# i2c_reva_me13 register map
Registers are 32-bit, access not given, no defined reset value unless marked. A register's access mark holds for its fields unless they carry their own. Offsets are from the block's base; lines under a group give offsets from that group; [hi:lo] are bit positions; {n}, {i} and the like mark numbered series; 'fields as' and 'values as' point back to an identical list; <NAME> marks a mode.

## Memory map
0x4001D000 I2C0 size 0x1000 — Inter-Integrated Circuit.

## Interrupts
13 I2C0 — I2C0 IRQ

## I2C0 — Inter-Integrated Circuit.
Base 0x4001D000
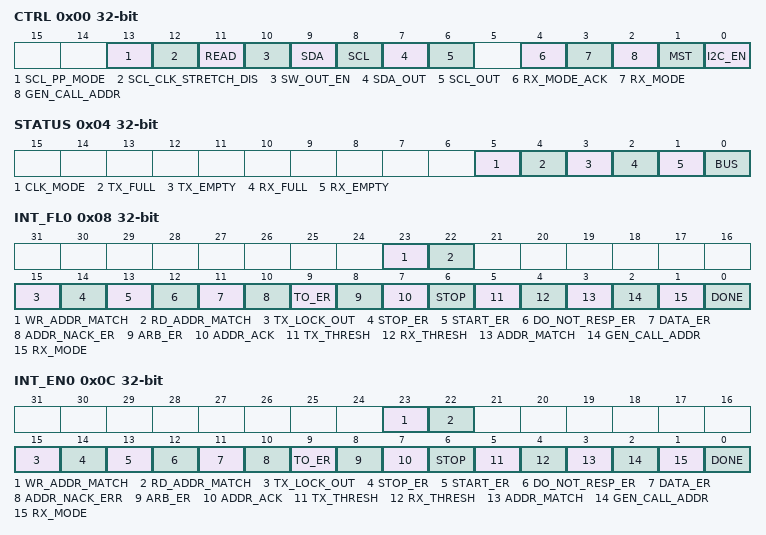
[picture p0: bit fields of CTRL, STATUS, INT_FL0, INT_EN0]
0x00 CTRL access per field — Control Register0.
  [13] SCL_PP_MODE rw — SCL Push-Pull Mode. This bit controls whether SCL is operated in a the I2C standard open-drain mode, or in a non-standard push-pull mode where the Hi-Z output isreplaced with Drive-1. The non-standard mode should only be used when operating as a master and communicating with slaves that are guaranteed to never drive SCL low.
    0=dis (Standard open-drain operation: drive low for 0, Hi-Z for 1); 1=en (Non-standard push-pull operation: drive low for 0, drive high for 1)
  [12] SCL_CLK_STRETCH_DIS rw — This bit will disable slave clock stretching when set.
    0=en (Slave clock stretching enabled.); 1=dis (Slave clock stretching disabled.)
  [11] READ ro — Read. This bit reflects the R/W bit of an address match (AMI = 1) or general call match (GCI = 1). This bit is valid 3 cycles after the relevant interrupt bit is set.
    0=write; 1=read
  [10] SW_OUT_EN rw — Software Output Enable.
    0=outputs_disable (I2C Outputs SCLO and SDAO disabled.); 1=outputs_enable (I2C Outputs SCLO and SDAO enabled.)
  [9] SDA ro — SDA status. THis bit reflects the logic gate of SDA signal.
  [8] SCL ro — SCL status. This bit reflects the logic gate of SCL signal.
  [7] SDA_OUT rw — SDA Output. This bits control SDA output when SWOE = 1.
    0=drive_sda_low; 1=release_sda
  [6] SCL_OUT rw — SCL Output. This bits control SCL output when SWOE =1.
    0=drive_scl_low; 1=release_scl
  [4] RX_MODE_ACK rw — Data Acknowledge. This bit defines the acknowledge bit returned by the I2C receiver while IRXM = 1 HW forces ACK to 0 when IRXM = 0.
    0=ack (return ACK (pulling SDA LOW).); 1=nack (return NACK (leaving SDA HIGH).)
  [3] RX_MODE rw — Interactive Receive Mode.
    0=dis (Disable Interactive Receive Mode.); 1=en (Enable Interactive Receive Mode.)
  [2] GEN_CALL_ADDR rw — General Call Address Enable.
    0=dis (Ignore Gneral Call Address.); 1=en (Acknowledge general call address.)
  [1] MST rw — Master Mode Enable.
    0=slave_mode; 1=master_mode
  [0] I2C_EN rw — I2C Enable.
    0=dis (Disable I2C.); 1=en (Enable I2C.)
0x04 STATUS
  [5] CLK_MODE ro — Clock Mode.
    0=not_actively_driving_scl_clock (Device not actively driving SCL clock cycles.); 1=actively_driving_scl_clock (Device operating as master and actively driving SCL clock cycles.)
  [4] TX_FULL
    0=not_empty; 1=empty
  [3] TX_EMPTY
    0=not_empty; 1=empty
  [2] RX_FULL ro
    0=not_full; 1=full
  [1] RX_EMPTY ro
    0=not_empty; 1=empty
  [0] BUS ro — Bus Status.
    0=idle (I2C Bus Idle.); 1=busy (I2C Bus Busy.)
0x08 INT_FL0 — Interrupt Status Register.
  [23] WR_ADDR_MATCH — Slave Write Address Match Interrupt
    0=no_match (No address match.); 1=match (Address match.)
  [22] RD_ADDR_MATCH — Slave Read Address Match Interrupt
    0=no_match (No address match.); 1=match (Address match.)
  [15] TX_LOCK_OUT — Transmit Lock Out Interrupt.
    0=unlocked (TX FIFO not locked.); 1=locked (TX FIFO locked.)
  [14] STOP_ER — Stop Error Interrupt.
    0=inactive (No Interrupt is Pending.); 1=pending (An interrupt is pending.)
  [13] START_ER — Start Error Interrupt.
    values as STOP_ER
  [12] DO_NOT_RESP_ER — Do Not Respond Error Interrupt.
    values as STOP_ER
  [11] DATA_ER — Data NACK Error Interrupt.
    values as STOP_ER
  [10] ADDR_NACK_ER — Address NACK Error Interrupt.
    values as STOP_ER
  [9] TO_ER — timeout Error Interrupt.
    values as STOP_ER
  [8] ARB_ER — Arbritation error Interrupt.
    values as STOP_ER
  [7] ADDR_ACK — Address Acknowledge Interrupt.
    values as STOP_ER
  [6] STOP — STOP Interrupt.
    0=inactive (No interrupt is pending.); 1=pending (An interrupt is pending. TX_FIFO has equal or less bytes than the threshold.)
  [5] TX_THRESH — Transmit Threshold Interrupt. This bit is automaticcaly cleared when TX_FIFO is above the threshold level.
    values as STOP
  [4] RX_THRESH — Receive Threshold Interrupt. This bit is automaticcaly cleared when RX_FIFO is below the threshold level.
    0=inactive (No interrupt is pending.); 1=pending (An interrupt is pending. RX_FIFO equal or more bytes than the threshold.)
  [3] ADDR_MATCH — Slave Address Match Interrupt.
    values as STOP_ER
  [2] GEN_CALL_ADDR — Slave General Call Address Match Interrupt.
    values as STOP_ER
  [1] RX_MODE — Interactive Receive Interrupt.
    values as STOP_ER
  [0] DONE — Transfer Done Interrupt.
    values as STOP_ER
0x0C INT_EN0 rw — Interrupt Enable Register.
  [23] WR_ADDR_MATCH — Slave Write Address Match Interrupt
    0=dis (Interrupt disabled.); 1=en (Interrupt enabled.)
  [22] RD_ADDR_MATCH — Slave Read Address Match Interrupt
    0=dis (Interrupt disabled.); 1=en (Interrupt enabled.)
  [15] TX_LOCK_OUT — TX FIFO Locked Out Interrupt.
    0=dis (Interrupt disabled.); 1=en (Interrupt enabled.)
  [14] STOP_ER — Out of Sequence STOP condition detected interrupt.
    0=dis (Interrupt disabled.); 1=en (Interrupt enabled.)
  [13] START_ER — Out of Sequence START condition detected interrupt.
    0=dis (Interrupt disabled.); 1=en (Interrupt enabled.)
  [12] DO_NOT_RESP_ER — Slave Mode Do Not Respond Interrupt.
    0=dis (Interrupt disabled.); 1=en (Interrupt enabled.)
  [11] DATA_ER — Master Mode Data NACK Received Interrupt.
    0=dis (Interrupt disabled.); 1=en (Interrupt enabled.)
  [10] ADDR_NACK_ERR — Master Mode Address NACK Received Interrupt.
    0=dis (Interrupt disabled.); 1=en (Interrupt enabled.)
  [9] TO_ER — Timeout Error Interrupt Enable.
    0=dis (Interrupt disabled.); 1=en (Interrupt enabled.)
  [8] ARB_ER — Master Mode Arbitration Lost Interrupt.
    0=dis (Interrupt disabled.); 1=en (Interrupt enabled.)
  [7] ADDR_ACK — Received Address ACK from Slave Interrupt.
    0=dis (Interrupt disabled.); 1=en (Interrupt enabled.)
  [6] STOP — Stop Interrupt Enable
    0=dis (Interrupt disabled.); 1=en (Interrupt enabled when STOP = 1.)
  [5] TX_THRESH — TX FIFO Below Treshold Level Interrupt Enable.
    0=dis (Interrupt disabled.); 1=en (Interrupt enabled.)
  [4] RX_THRESH — RX FIFO Above Treshold Level Interrupt Enable.
    0=dis (Interrupt disabled.); 1=en (Interrupt enabled.)
  [3] ADDR_MATCH — Slave mode incoming address match interrupt.
    0=dis (Interrupt disabled.); 1=en (Interrupt enabled when ADDR_MATCH = 1.)
  [2] GEN_CALL_ADDR — Slave mode general call address match received input enable.
    0=dis (Interrupt disabled.); 1=en (Interrupt enabled when GEN_CTRL_ADDR = 1.)
  [1] RX_MODE
    0=dis (Interrupt disabled.); 1=en (Interrupt enabled when RX_MODE = 1.)
  [0] DONE — Transfer Done Interrupt Enable.
    0=dis (Interrupt disabled.); 1=en (Interrupt enabled when DONE = 1.)
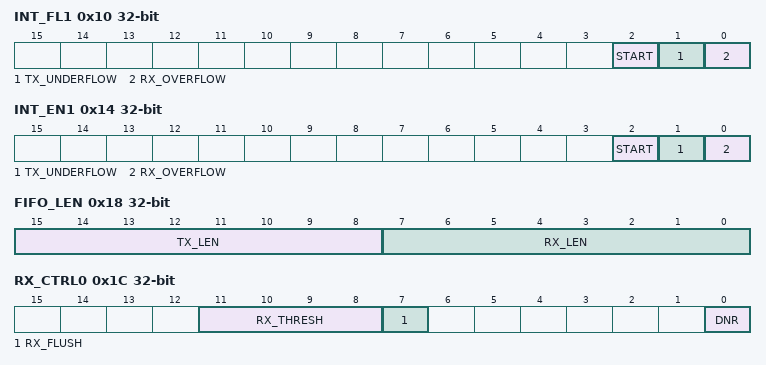
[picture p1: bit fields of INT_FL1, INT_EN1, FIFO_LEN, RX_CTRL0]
0x10 INT_FL1 — Interrupt Status Register 1.
  [2] START — START Condition Status Flag.
    0=not_detected (START condition not detected.); 1=detected (START condition detected.)
  [1] TX_UNDERFLOW — Transmit Underflow Interrupt. When operating as a slave transmitter, this bit is set when you reach the first data bit and the TX FIFO is empty and the master is still asking for more data (i.e the master hasn't sent a NACK yet).
    values as INT_FL0.STOP_ER
  [0] RX_OVERFLOW — Receiver Overflow Interrupt. When operating as a slave receiver, this bit is set when you reach the first data bit and the RX FIFO and shift register are both full.
    values as INT_FL0.STOP_ER
0x14 INT_EN1 rw — Interrupt Staus Register 1.
  [2] START — START Condition Interrupt Enable.
    0=dis (Disable START condition interrupt.); 1=en (Enable START condition interrupt.)
  [1] TX_UNDERFLOW — Transmit Underflow Interrupt Enable.
    0=dis (No Interrupt is Pending.); 1=en (An interrupt is pending.)
  [0] RX_OVERFLOW — Receiver Overflow Interrupt Enable.
    values as TX_UNDERFLOW
0x18 FIFO_LEN ro — FIFO Configuration Register.
  [15:8] TX_LEN — Transmit FIFO Length.
  [7:0] RX_LEN — Receive FIFO Length.
0x1C RX_CTRL0 — Receive Control Register 0.
  [11:8] RX_THRESH — Receive FIFO Threshold. These bits define the RX_FIFO interrupt threshold.
  [7] RX_FLUSH — Receive FIFO Flush. This bit is automatically cleared to 0 after the operation. Setting this bit to 1 will affect RX_FIFO status.
    0=not_flushed (FIFO not flushed.); 1=Flush RX_FIFO
  [0] DNR — Do Not Respond.
    0=respond (Always respond to address match.); 1=not_respond_rx_fifo_empty (Do not respond to address match when RX_FIFO is not empty.)
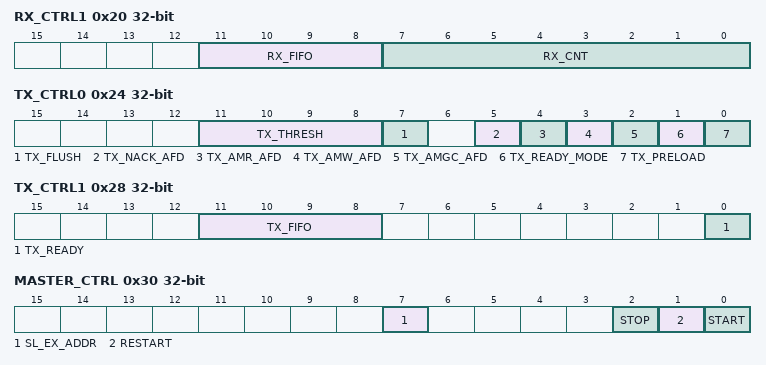
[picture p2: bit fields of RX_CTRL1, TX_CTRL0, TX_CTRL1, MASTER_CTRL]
0x20 RX_CTRL1 — Receive Control Register 1.
  [11:8] RX_FIFO ro — Receive FIFO Count. These bits reflect the number of byte in the RX_FIFO. These bits are flushed when I2CEN = 0.
  [7:0] RX_CNT — Receive Count Bits. These bits define the number of bytes to be received in a transaction, except for the case RXCNT = 0. RXCNT = 0 means 256 bytes to be received in a transaction.
0x24 TX_CTRL0 — Transmit Control Register 0.
  [11:8] TX_THRESH — Transmit FIFO Threshold. These bits define the TX_FIFO interrupt threshold.
  [7] TX_FLUSH — Transmit FIFO Flush. This bit is automatically cleared to 0 after the operation.
    0=not_flushed (FIFO not flushed.); 1=Flush TX_FIFO
  [5] TX_NACK_AFD — TX FIFO received NACK Auto Flush Disable.
    0=en (Enabled.); 1=dis (Disabled.)
  [4] TX_AMR_AFD — TX FIFO Slave Address Match Read Auto Flush Disable.
    0=en (Enabled.); 1=dis (Disabled.)
  [3] TX_AMW_AFD — TX FIFO Slave Address Match Write Auto Flush Disable.
    0=en (Enabled.); 1=dis (Disabled.)
  [2] TX_AMGC_AFD — TX FIFO General Call Address Match Auto Flush Disable.
    0=en (Enabled.); 1=dis (Disabled.)
  [1] TX_READY_MODE — Transmit FIFO Ready Manual Mode.
    0=en (HW control of I2CTXRDY enabled.); 1=dis (HW control of I2CTXRDY disabled.)
  [0] TX_PRELOAD — Transmit FIFO Preaload Mode. Setting this bit will allow for high speed application to preload the transmit FIFO prior to Slave Address Match.
0x28 TX_CTRL1 — Transmit Control Register 1.
  [11:8] TX_FIFO ro — Transmit FIFO Count. These bits reflect the number of bytes in the TX_FIFO.
  [0] TX_READY — Transmit FIFO Preload Ready.
0x2C FIFO — Data Register.
  [7:0] DATA — Data is read from or written to this location. Transmit and receive FIFO are separate but both are addressed at this location.
0x30 MASTER_CTRL — Master Control Register.
  [7] SL_EX_ADDR — Slave Extend Address Select.
    0=7_bits_address (7-bit address.); 1=10_bits_address (10-bit address.)
  [2] STOP — Setting this bit to 1 will generate a STOP condition.
  [1] RESTART — Setting this bit to 1 will generate a repeated START.
  [0] START — Setting this bit to 1 will start a master transfer.
0x34 CLK_LO — Clock Low Register.
  [8:0] SCL_LO — Clock low. In master mode, these bits define the SCL low period. In slave mode, these bits define the time SCL will be held low after data is outputted.
0x38 CLK_HI — Clock high Register.
  [8:0] SCL_HI — Clock High. In master mode, these bits define the SCL high period.
0x40 TIMEOUT
  [15:0] TO — Timeout
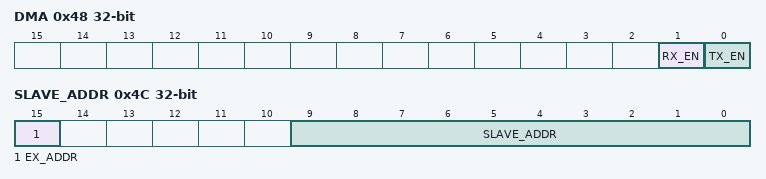
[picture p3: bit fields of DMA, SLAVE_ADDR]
0x48 DMA
  [1] RX_EN — RX channel enable.
    0=dis (Disable.); 1=en (Enable.)
  [0] TX_EN — TX channel enable.
    0=dis (Disable.); 1=en (Enable.)
0x4C SLAVE_ADDR — Slave Address Register.
  [15] EX_ADDR — Extended Address Select.
    values as MASTER_CTRL.SL_EX_ADDR
  [9:0] SLAVE_ADDR — Slave Address.
